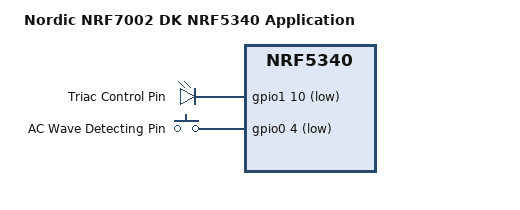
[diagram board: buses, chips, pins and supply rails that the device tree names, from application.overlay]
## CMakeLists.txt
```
#
# Copyright (c) 2021 Nordic Semiconductor ASA
#
# SPDX-License-Identifier: LicenseRef-Nordic-5-Clause
#

cmake_minimum_required(VERSION 3.20.0)

# Set Kconfig root files that will be processed as a first Kconfig for used child images.
set(mcuboot_KCONFIG_ROOT "\\\${ZEPHYR_CONNECTEDHOMEIP_MODULE_DIR}/config/nrfconnect/chip-module/Kconfig.mcuboot.root")
set(multiprotocol_rpmsg_KCONFIG_ROOT "\\\${ZEPHYR_CONNECTEDHOMEIP_MODULE_DIR}/config/nrfconnect/chip-module/Kconfig.multiprotocol_rpmsg.root")
set(hci_ipc_KCONFIG_ROOT "\\\${ZEPHYR_CONNECTEDHOMEIP_MODULE_DIR}/config/nrfconnect/chip-module/Kconfig.hci_ipc.root")

# For prj.conf the CONF_FILE is empty. In other case extract the exact file name from the path string.
if(CONF_FILE)
    get_filename_component(CONFIG_FILE_NAME ${CONF_FILE} NAME)
endif()

if(NOT "${CONFIG_FILE_NAME}" STREQUAL "prj_no_dfu.conf")
    set(PM_STATIC_YML_FILE ${CMAKE_CURRENT_SOURCE_DIR}/configuration/${BOARD}/pm_static_dfu.yml)
endif()

find_package(Zephyr HINTS $ENV{ZEPHYR_BASE})

project(matter-light-bulb)

# Enable GNU STD support and initialize the Matter Data Model.
include(${ZEPHYR_CONNECTEDHOMEIP_MODULE_DIR}/config/nrfconnect/app/enable-gnu-std.cmake)
include(${ZEPHYR_CONNECTEDHOMEIP_MODULE_DIR}/src/app/chip_data_model.cmake)

# NORDIC SDK APP START

# Include all source files that are located in the Matter common directory.
include(${ZEPHYR_NRF_MODULE_DIR}/samples/matter/common/cmake/source_common.cmake)

target_include_directories(app PRIVATE
    src
    src/bridged_device_types
    ${ZEPHYR_NRF_MODULE_DIR}/samples/matter/common/src/bridge/
    ${ZEPHYR_NRF_MODULE_DIR}/samples/matter/common/src/bridge/util
)

if(CONFIG_AWS_IOT_INTEGRATION)
    add_subdirectory(src/aws_iot_integration)
endif()

target_sources(app PRIVATE
    src/app_task.cpp
    src/main.cpp
    src/zcl_callbacks.cpp
    src/triac_controller.c
    src/ac_wave_detector.c
    src/bridge_shell.cpp
    ${ZEPHYR_NRF_MODULE_DIR}/samples/matter/common/src/bridge/bridge_manager.cpp
    ${ZEPHYR_NRF_MODULE_DIR}/samples/matter/common/src/bridge/matter_bridged_device.cpp
    ${ZEPHYR_NRF_MODULE_DIR}/samples/matter/common/src/bridge/bridge_storage_manager.cpp
    ${ZEPHYR_NRF_MODULE_DIR}/samples/matter/common/src/bridge/bridged_device_data_provider.cpp
    ${ZEPHYR_NRF_MODULE_DIR}/samples/matter/common/src/binding/binding_handler.cpp
    ${ZEPHYR_NRF_MODULE_DIR}/samples/matter/common/src/persistent_storage/persistent_storage_util.cpp
)

if(CONFIG_BRIDGED_DEVICE_BT)
    target_sources(app PRIVATE
         ${ZEPHYR_NRF_MODULE_DIR}/samples/matter/common/src/bridge/ble_connectivity_manager.cpp
        src/ble_providers/ble_bridged_device_factory.cpp
    )
    target_include_directories(app PRIVATE src/ble_providers)

if(CONFIG_BRIDGE_ONOFF_LIGHT_BRIDGED_DEVICE AND (CONFIG_BRIDGE_GENERIC_SWITCH_BRIDGED_DEVICE OR CONFIG_BRIDGE_ONOFF_LIGHT_SWITCH_BRIDGED_DEVICE))
    target_sources(app PRIVATE
        src/bridged_device_types/onoff_light.cpp
        src/ble_providers/ble_lbs_data_provider.cpp
    )

if(CONFIG_BRIDGE_GENERIC_SWITCH_BRIDGED_DEVICE)
    target_sources(app PRIVATE src/bridged_device_types/generic_switch.cpp)
endif()

if(CONFIG_BRIDGE_ONOFF_LIGHT_SWITCH_BRIDGED_DEVICE)
    target_sources(app PRIVATE
        src/bridged_device_types/onoff_light_switch.cpp
    )
endif()

endif() # CONFIG_BRIDGE_ONOFF_LIGHT_BRIDGED_DEVICE AND (CONFIG_BRIDGE_GENERIC_SWITCH_BRIDGED_DEVICE OR CONFIG_BRIDGE_ONOFF_LIGHT_SWITCH_BRIDGED_DEVICE)

if(CONFIG_BRIDGE_HUMIDITY_SENSOR_BRIDGED_DEVICE)
    target_sources(app PRIVATE
        src/bridged_device_types/humidity_sensor.cpp
    )
endif() # CONFIG_BRIDGE_HUMIDITY_SENSOR_BRIDGED_DEVICE

if(CONFIG_BRIDGE_TEMPERATURE_SENSOR_BRIDGED_DEVICE)
    target_sources(app PRIVATE
        src/bridged_device_types/temperature_sensor.cpp
    )
endif() # CONFIG_BRIDGE_TEMPERATURE_SENSOR_BRIDGED_DEVICE

# Assume it makes no sense to support BLE environmental sensor without all Matter counterparts
if(CONFIG_BRIDGE_TEMPERATURE_SENSOR_BRIDGED_DEVICE AND CONFIG_BRIDGE_HUMIDITY_SENSOR_BRIDGED_DEVICE)
    target_sources(app PRIVATE
        src/ble_providers/ble_environmental_data_provider.cpp
    )
endif() # CONFIG_BRIDGE_TEMPERATURE_SENSOR_BRIDGED_DEVICE AND CONFIG_BRIDGE_HUMIDITY_SENSOR_BRIDGED_DEVICE

else()
    target_sources(app PRIVATE
        src/simulated_providers/simulated_bridged_device_factory.cpp
    )
    target_include_directories(app PRIVATE src/simulated_providers)

if(CONFIG_BRIDGE_ONOFF_LIGHT_BRIDGED_DEVICE AND (CONFIG_BRIDGE_GENERIC_SWITCH_BRIDGED_DEVICE OR CONFIG_BRIDGE_ONOFF_LIGHT_SWITCH_BRIDGED_DEVICE))
    target_sources(app PRIVATE
        src/bridged_device_types/onoff_light.cpp
        src/simulated_providers/simulated_onoff_light_data_provider.cpp
    )

if(CONFIG_BRIDGE_GENERIC_SWITCH_BRIDGED_DEVICE)
    target_sources(app PRIVATE
        src/bridged_device_types/generic_switch.cpp
        src/simulated_providers/simulated_generic_switch_data_provider.cpp
    )
endif()

if(CONFIG_BRIDGE_ONOFF_LIGHT_SWITCH_BRIDGED_DEVICE)
    target_sources(app PRIVATE
        src/bridged_device_types/onoff_light_switch.cpp
        src/simulated_providers/simulated_onoff_light_switch_data_provider.cpp
    )
endif()

endif() # CONFIG_BRIDGE_ONOFF_LIGHT_BRIDGED_DEVICE AND (CONFIG_BRIDGE_GENERIC_SWITCH_BRIDGED_DEVICE OR CONFIG_BRIDGE_ONOFF_LIGHT_SWITCH_BRIDGED_DEVICE))

if(CONFIG_BRIDGE_TEMPERATURE_SENSOR_BRIDGED_DEVICE)
    target_sources(app PRIVATE
            src/bridged_device_types/temperature_sensor.cpp
            src/simulated_providers/simulated_temperature_sensor_data_provider.cpp
    )
endif() # CONFIG_BRIDGE_TEMPERATURE_SENSOR_BRIDGED_DEVICE

if(CONFIG_BRIDGE_HUMIDITY_SENSOR_BRIDGED_DEVICE)
    target_sources(app PRIVATE
        src/bridged_device_types/humidity_sensor.cpp
        src/simulated_providers/simulated_humidity_sensor_data_provider.cpp
    )
endif() # CONFIG_BRIDGE_HUMIDITY_SENSOR_BRIDGED_DEVICE

endif() # CONFIG_BRIDGED_DEVICE_BT

chip_configure_data_model(app
    INCLUDE_SERVER
    BYPASS_IDL
    GEN_DIR src/zap-generated
    ZAP_FILE ${CMAKE_CURRENT_SOURCE_DIR}/src/light_bulb.zap
)
# NORDIC SDK APP END
```

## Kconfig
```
#
# Copyright (c) 2022 Nordic Semiconductor
#
# SPDX-License-Identifier: LicenseRef-Nordic-5-Clause
#
mainmenu "Matter nRF Connect Light Bulb Example Application"

# Sample configuration used for Thread networking
if NET_L2_OPENTHREAD

choice OPENTHREAD_NORDIC_LIBRARY_CONFIGURATION
	default OPENTHREAD_NORDIC_LIBRARY_FTD
endchoice

choice OPENTHREAD_DEVICE_TYPE
	default OPENTHREAD_FTD
endchoice

endif # NET_L2_OPENTHREAD

config BRIDGE_ONOFF_LIGHT_BRIDGED_DEVICE
	bool "Support for OnOff Light bridged device"
	default y

config BRIDGE_TEMPERATURE_SENSOR_BRIDGED_DEVICE
	bool "Support for Temperature Sensor bridged device"
	default y

config BRIDGE_HUMIDITY_SENSOR_BRIDGED_DEVICE
	bool "Support for Humidity Sensor bridged device"
	default y

choice BRIDGE_SWITCH_BRIDGED_DEVICE
	prompt "Bridged device switch implementation"
	default BRIDGE_GENERIC_SWITCH_BRIDGED_DEVICE

config BRIDGE_GENERIC_SWITCH_BRIDGED_DEVICE
	bool "Support for Generic Switch bridged device"

config BRIDGE_ONOFF_LIGHT_SWITCH_BRIDGED_DEVICE
	bool "Support for OnOff Light Switch bridged device"

endchoice

choice BRIDGED_DEVICE_IMPLEMENTATION
	prompt "Bridged Device implementation"
	default BRIDGED_DEVICE_SIMULATED

	config BRIDGED_DEVICE_SIMULATED
		bool "Simulated Bridged Device"
		help
		  Enables using simulated bridged devices that do not perform
		  real operations, but emulate exemplary data to imitate the real
		  device behavior.

	config BRIDGED_DEVICE_BT
		bool "Bluetooth LE Bridged Device"
		help
		  Enables using real bridged devices that communicate with the Matter bridge device
		  over Bluetooth LE.

endchoice

if BRIDGED_DEVICE_SIMULATED

choice BRIDGED_DEVICE_SIMULATED_ONOFF_IMPLEMENTATION
	prompt "Simulated bridged onoff device implementation"
	default BRIDGED_DEVICE_SIMULATED_ONOFF_SHELL

	config BRIDGED_DEVICE_SIMULATED_ONOFF_AUTOMATIC
		bool "Automatically simulated bridged onoff device"
		help
		  Enables using simulated bridged onoff device that
		  automatically changes its state periodically.

	config BRIDGED_DEVICE_SIMULATED_ONOFF_SHELL
		bool "Shell controlled simulated bridged onoff device"
		help
		  Enables using simulated bridged onoff device that is
		  controlled by shell commands.

endchoice

endif

if BRIDGED_DEVICE_BT

config BT_CENTRAL
	default y

config BT_SCAN
	default y

# Configure how many Bluetooth LE devices the Matter bridge can support (the final number is given value - 1, as 1 connection is used for the Matter Bluetooth LE service).
config BT_MAX_CONN
	default 6

config BT_SCAN_FILTER_ENABLE
	default y

# Configure how many Bluetooth LE service UUIDs the Matter bridge can scan.
config BT_SCAN_UUID_CNT
	default 2

config BT_SCAN_ADDRESS_CNT
	default 1

config BT_GATT_CLIENT
	default y

config BT_GATT_DM
	default y

config BT_EXT_ADV
	default y

config BT_SMP
	default y

if BT_SMP

config BT_SETTINGS
	default y

# Configure how many Bluetooth LE devices will be paired with Matter bridge. Assuming it will be only bridged devices, it should be set to BT_MAX_CONN - 1.
config BT_MAX_PAIRED
	default 2

# Use two Bluetooth LE identities. The first one is used by the peripheral for Matter service advertising purposes, and the other is used by the Matter bridge central.
config BT_ID_MAX
	default 2

config BT_EXT_ADV_LEGACY_SUPPORT
	default y

endif

config BRIDGE_BLE_DEVICE_POLLING_INTERVAL
	int "BLE humidity measurement readout polling interval in ms"
	default 3000

endif

if BRIDGE_TEMPERATURE_SENSOR_BRIDGED_DEVICE

config BRIDGE_TEMPERATURE_SENSOR_MIN_MEASURED_VALUE
	int "Default minimum measured value allowed by the bridged temperature sensor device"
	default -20

config BRIDGE_TEMPERATURE_SENSOR_MAX_MEASURED_VALUE
	int "Default maximum measured value allowed by the bridged temperature sensor device"
	default 60

endif

if BRIDGE_HUMIDITY_SENSOR_BRIDGED_DEVICE

config BRIDGE_HUMIDITY_SENSOR_MIN_MEASURED_VALUE
	int "Default minimum measured value allowed by the bridged humidity sensor device"
	default 0

config BRIDGE_HUMIDITY_SENSOR_MAX_MEASURED_VALUE
	int "Default maximum measured value allowed by the bridged humidity sensor device"
	default 100

endif

# Enable Read Client functionality for all build configurations.
config CHIP_ENABLE_READ_CLIENT
	default y

source "${ZEPHYR_CONNECTEDHOMEIP_MODULE_DIR}/config/nrfconnect/chip-module/Kconfig.features"
source "${ZEPHYR_CONNECTEDHOMEIP_MODULE_DIR}/config/nrfconnect/chip-module/Kconfig.defaults"
source "${ZEPHYR_NRF_MODULE_DIR}/samples/matter/common/src/bridge/Kconfig"
source "${ZEPHYR_NRF_MODULE_DIR}/samples/matter/common/src/Kconfig"
source "Kconfig.zephyr"
rsource "src/aws_iot_integration/Kconfig"
```

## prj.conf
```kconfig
#
# Copyright (c) 2022 Nordic Semiconductor ASA
#
# SPDX-License-Identifier: LicenseRef-Nordic-5-Clause
#
CONFIG_LOG=y

# Enable CHIP
CONFIG_CHIP=y
CONFIG_CHIP_PROJECT_CONFIG="src/chip_project_config.h"
# 32773 == 0x8005 (example lighting-app)
CONFIG_CHIP_DEVICE_PRODUCT_ID=32773
CONFIG_STD_CPP17=y

# Enable CHIP pairing automatically on application start.
CONFIG_CHIP_ENABLE_PAIRING_AUTOSTART=y

# Add support for LEDs and buttons on Nordic development kits
CONFIG_DK_LIBRARY=n
CONFIG_PWM=y

# Bluetooth Low Energy configuration
CONFIG_BT_DEVICE_NAME="MatterLight"

# Other settings
CONFIG_THREAD_NAME=y
CONFIG_MPU_STACK_GUARD=y
CONFIG_RESET_ON_FATAL_ERROR=n
CONFIG_CHIP_LIB_SHELL=y

# Reduce application size
CONFIG_USE_SEGGER_RTT=n

# Enable Factory Data feature
CONFIG_CHIP_FACTORY_DATA=y
CONFIG_CHIP_FACTORY_DATA_BUILD=y

CONFIG_MCUBOOT_IMGTOOL_SIGN_VERSION="2.6.0+0"

CONFIG_ASSERT_NO_FILE_INFO=y
CONFIG_CHIP_NFC_COMMISSIONING=n
CONFIG_BRIDGED_DEVICE_BT=y
```

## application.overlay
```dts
/ {
  model = "Nordic NRF7002 DK NRF5340 Application";
  compatible = "nordic,nrf7002-dk-nrf5340-cpuapp";

  leds {
    compatible = "gpio-leds";
    led0: led_0 {
      gpios = <&gpio1 10 GPIO_ACTIVE_LOW>;
      label = "Triac Control Pin";
    };
  };

  buttons {
    compatible = "gpio-keys";
    button0: button_0 {
      gpios = <&gpio0 4 (GPIO_ACTIVE_LOW)>;
      label = "AC Wave Detecting Pin";
    };
  };
};
```

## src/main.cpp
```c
/*
 * Copyright (c) 2021 Nordic Semiconductor ASA
 *
 * SPDX-License-Identifier: LicenseRef-Nordic-5-Clause
 */

extern "C" {
	#include "ac_wave_detector.h"
	#include "triac_controller.h"
}

#include "app_task.h"

#include <zephyr/logging/log.h>

LOG_MODULE_REGISTER(app, CONFIG_CHIP_APP_LOG_LEVEL);

void new_ac_wave_detected(void)
{
	start_triac_on_timer();
}

int main()
{
	int err_c;
	err_c = init_ac_wave_detector(new_ac_wave_detected);
	if(err_c)
	{
		printk("Failed to init ac wave detector\n");
		return err_c;
	}

	err_c = init_triac_controller();
	if(err_c)
	{
		printk("Failed to init triac controller\n");
		return err_c;
	}

	enable_ac_wave_detector();

	change_triac_enabled_state(true);
	change_triac_brightness_level(10);

 	k_msleep(1000);

	CHIP_ERROR err = AppTask::Instance().StartApp();

	LOG_ERR("Exited with code %" CHIP_ERROR_FORMAT, err.Format());
	return err == CHIP_NO_ERROR ? EXIT_SUCCESS : EXIT_FAILURE;
}
```

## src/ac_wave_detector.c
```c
/******************************************************************************************
 *
 * @file        ac_wave_detector.h
 *
 * @brief       Detects new AC wave signal
 *
 * @details     Calls the callback provided when a new AC wave is detected
 *
 * @author(s)   Joe Rippee
 *
 * @created     2/09/2024   (MM/DD/YYYY)
 * 
 * @copyright       © 2024 SWYM, LLC. All Rights Reserved
 *
 *****************************************************************************************/

#include <zephyr/drivers/gpio.h>
#include <zephyr/kernel.h>
#include <zephyr/sys/printk.h>

#include "ac_wave_detector.h"

#define AC_WAVE_STACK_SIZE  1024
#define AC_WAVE_THD_PRIO    10

/*
 * Get button configuration from the devicetree sw0 alias. This is mandatory.
 */
#define SW0_NODE        DT_ALIAS(sw0)
#if !DT_NODE_HAS_STATUS(SW0_NODE, okay)
#error "Unsupported board: sw0 devicetree alias is not defined"
#endif

K_THREAD_STACK_DEFINE(ac_wave_stack, AC_WAVE_STACK_SIZE);
struct k_work_q ac_wave_q;

static struct k_work ac_wave_handler;

static const struct gpio_dt_spec ac_wave_detector_gpio = GPIO_DT_SPEC_GET_OR(SW0_NODE, gpios,
                                                              {0});
static struct gpio_callback ac_wave_cb_data;

void (*main_ac_wave_detected_callback)(void) = NULL;

/*
  Parameter: k_work pointer
  Returns: N/A

  gets called by a work queue if new AC wave is detected
  simply alerts the main program that a new AC wave was detected
*/
void ac_wave_work_handler(struct k_work *work) {
  if(NULL != main_ac_wave_detected_callback) {
    main_ac_wave_detected_callback();
  }
}

/*
  Parameter: 
    which button port was pressed/depressed
    a struct holding gpio callback info
    which button pin was pressed/depressed
  Returns: N/A

  Triggers on button rising and falling edge
  The onboard press detect chip seems to handle de-bounce quite well

  If button is pressed, start a timer
  If button is de-pressed, end timer
*/
void ac_wave_detected(const struct device *dev, struct gpio_callback *cb,
                    uint32_t pins)
{
  int val = gpio_pin_get_dt(&ac_wave_detector_gpio);
  if (val >= 0) {
    int k_work_status = k_work_submit_to_queue(&ac_wave_q, &ac_wave_handler);
    if(0 > k_work_status) {
      printk("[ac_wave_detector]: Could not submit ac wave detection to queue due to %i!\n", k_work_status);
    }
  }
}

/*
  Parameter: N/A
  Returns: status variable for capacative button enable GPIO initialization

  this GPIO must be high for button detection to work due to the PCB layout
  returns 0 if initialization was successful
*/
/*
  Parameter: N/A
  Returns: status variable for capacative button GPIO initialization

  enables the capacative button on the wristband
  provides callback for when button is pressed/depressed
  returns 0 if initialization was successful
*/
int initialize_ac_detect_gpio(void)
{
  int err = 0;

  if (!gpio_is_ready_dt(&ac_wave_detector_gpio)) {
    printk("Error: ac_wave_detector_gpio device %s is not ready\n",
           ac_wave_detector_gpio.port->name);
    err += -ENODEV;
  }
  
  err += gpio_pin_configure_dt(&ac_wave_detector_gpio, GPIO_INPUT);
  if (err != 0) {
    printk("Error %d: failed to configure %s pin %d\n",
           err, ac_wave_detector_gpio.port->name, ac_wave_detector_gpio.pin);
  }
  
  err += gpio_pin_interrupt_configure_dt(&ac_wave_detector_gpio,
                                      GPIO_INT_EDGE_FALLING);
  if (err != 0) {
    printk("Error %d: failed to configure interrupt on %s pin %d\n",
        err, ac_wave_detector_gpio.port->name, ac_wave_detector_gpio.pin);
  }
  
  gpio_init_callback(&ac_wave_cb_data, ac_wave_detected, BIT(ac_wave_detector_gpio.pin));

  return err;
}

/*
  Parameter: void function pointer for when new AC wave is detected
  Returns: status variable for ac wave detection initialization. 0 = success

  Initializes the ac wave detector with edge detect interrupts (rising edge only)
  Provided callback is stored in a unique private function pointer
*/
int init_ac_wave_detector(void (*ac_wave_detected_callback)(void))
{
  int err = 0;

  main_ac_wave_detected_callback = ac_wave_detected_callback;
  err += initialize_ac_detect_gpio();

  if(0 == err) {
    k_work_init(&ac_wave_handler, ac_wave_work_handler);

    k_work_queue_start(
      &ac_wave_q,
      ac_wave_stack,
      K_THREAD_STACK_SIZEOF(ac_wave_stack),
      AC_WAVE_THD_PRIO,
      NULL
    );
  }

  return err;
}

void enable_ac_wave_detector(void)
{
  gpio_add_callback(ac_wave_detector_gpio.port, &ac_wave_cb_data);
}
```

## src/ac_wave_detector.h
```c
/******************************************************************************************
 *
 * @file        ac_wave_detector.h
 *
 * @brief       Detects new AC wave signal
 *
 * @details     Calls the callback provided when a new AC wave is detected
 *
 * @author(s)   Joe Rippee
 *
 * @created     2/09/2024   (MM/DD/YYYY)
 * 
 * @copyright       © 2024 SWYM, LLC. All Rights Reserved
 *
 *****************************************************************************************/

#ifndef AC_WAVE_DETECTOR_H__
#define AC_WAVE_DETECTOR_H__

/*
  Parameter: void function pointer for when new AC wave is detected
  Returns: status variable for ac wave detection initialization. 0 = success

  Initializes the ac wave detector with edge detect interrupts (rising edge only)
  Provided callback is stored in a unique private function pointer
*/
int init_ac_wave_detector(void (*ac_wave_detected_callback)(void));

void enable_ac_wave_detector(void);

#endif
```

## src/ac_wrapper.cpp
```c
#include "ac_wrapper.h"

AcWrapper* AcWrapper::instance = nullptr;

AcWrapper::AcWrapper() {
    instance = this;
}

AcWrapper::~AcWrapper() {
    instance = nullptr;
}

int AcWrapper::init(std::function<void()> callback) {
    this->acWaveDetectedCallback = callback;
    return init_ac_wave_detector(cStyleCallback);
}

void AcWrapper::enable() {
    enable_ac_wave_detector();
}

void AcWrapper::cStyleCallback() {
    if (instance != nullptr && instance->acWaveDetectedCallback) {
        instance->acWaveDetectedCallback();
    }
}
```

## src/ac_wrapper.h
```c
#ifndef AC_WRAPPER_H
#define AC_WRAPPER_H

#include <functional>

extern "C" {
    #include "ac_wave_detector.h"
}

class AcWrapper {
public:
    AcWrapper();
    ~AcWrapper();

    int init(std::function<void()> acWaveDetectedCallback);
    void enable();

private:
    static void cStyleCallback();

    std::function<void()> acWaveDetectedCallback;
    static AcWrapper* instance;
};

#endif // AC_WRAPPER_H
```

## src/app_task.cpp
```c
/*
 * Copyright (c) 2021 Nordic Semiconductor ASA
 *
 * SPDX-License-Identifier: LicenseRef-Nordic-5-Clause
 */

#include "app_task.h"

#ifdef CONFIG_BRIDGED_DEVICE_BT
#include "ble_bridged_device_factory.h"
#else
#include "simulated_bridged_device_factory.h"
#endif /* CONFIG_BRIDGED_DEVICE_BT */

#ifdef CONFIG_AWS_IOT_INTEGRATION
#include "aws_iot_integration.h"
#endif

#include "app/matter_init.h"
#include "app/task_executor.h"
#include "board/board.h"
#include "bridge/bridge_manager.h"
#include "bridge/bridge_storage_manager.h"
#include "pwm/pwm_device.h"

#ifdef CONFIG_BRIDGED_DEVICE_BT
#include "bridge/ble_connectivity_manager.h"
#endif

#ifdef CONFIG_CHIP_OTA_REQUESTOR
#include "dfu/ota/ota_util.h"
#endif

#include <app-common/zap-generated/ids/Attributes.h>
#include <app-common/zap-generated/ids/Clusters.h>
#include <app/server/OnboardingCodesUtil.h>

#include <app-common/zap-generated/attributes/Accessors.h>
#include <app/DeferredAttributePersistenceProvider.h>
#include <app/clusters/identify-server/identify-server.h>
#include <app/server/OnboardingCodesUtil.h>
#include <app/server/Server.h>

#ifdef CONFIG_BRIDGED_DEVICE_BT
#include <bluetooth/services/lbs.h>
#endif /* CONFIG_BRIDGED_DEVICE_BT */
#include <zephyr/logging/log.h>

LOG_MODULE_DECLARE(app, CONFIG_CHIP_APP_LOG_LEVEL);

using namespace ::chip;
using namespace ::chip::app;
using namespace ::chip::DeviceLayer;

namespace
{
#ifdef CONFIG_BRIDGED_DEVICE_BT
static bt_uuid *sUuidLbs = BT_UUID_LBS;
static bt_uuid *sUuidEs = BT_UUID_ESS;
static bt_uuid *sUuidServices[] = { sUuidLbs, sUuidEs };
static constexpr uint8_t kUuidServicesNumber = ARRAY_SIZE(sUuidServices);
/**
 * @brief Blink rates for indication the BLE Connectivity Manager state.
 *
 */
constexpr static uint32_t kPairingBlinkRate{ 100 };
constexpr static uint32_t kScanningBlinkRate_ms{ 300 };
constexpr static uint32_t kLostBlinkRate_ms{ 1000 };

void BLEStateChangeCallback(Nrf::BLEConnectivityManager::State state)
{
	switch (state) {
	case Nrf::BLEConnectivityManager::State::Connected:
		Nrf::PostTask([] { Nrf::GetBoard().GetLED(Nrf::DeviceLeds::LED2).Set(true); });
		break;
	case Nrf::BLEConnectivityManager::State::Scanning:
		Nrf::PostTask([] {
			Nrf::GetBoard()
				.GetLED(Nrf::DeviceLeds::LED2)
				.Blink(kScanningBlinkRate_ms, kScanningBlinkRate_ms);
		});
		break;
	case Nrf::BLEConnectivityManager::State::LostDevice:
		Nrf::PostTask([] {
			Nrf::GetBoard().GetLED(Nrf::DeviceLeds::LED2).Blink(kLostBlinkRate_ms, kLostBlinkRate_ms);
		});
		break;
	case Nrf::BLEConnectivityManager::State::Pairing:
		Nrf::PostTask([] {
			Nrf::GetBoard().GetLED(Nrf::DeviceLeds::LED2).Blink(kPairingBlinkRate, kPairingBlinkRate);
		});
		break;
	default:
		Nrf::PostTask([] { Nrf::GetBoard().GetLED(Nrf::DeviceLeds::LED2).Set(false); });
	}
}

#endif /* CONFIG_BRIDGED_DEVICE_BT */

constexpr EndpointId kLightEndpointId = 1;
constexpr uint8_t kDefaultMinLevel = 0;
constexpr uint8_t kDefaultMaxLevel = 254;
constexpr uint16_t kTriggerEffectTimeout = 5000;
constexpr uint16_t kTriggerEffectFinishTimeout = 1000;

k_timer sTriggerEffectTimer;

Identify sIdentify = { kLightEndpointId, AppTask::IdentifyStartHandler, AppTask::IdentifyStopHandler,
		       Clusters::Identify::IdentifyTypeEnum::kVisibleIndicator, AppTask::TriggerIdentifyEffectHandler };

bool sIsTriggerEffectActive = false;

const struct pwm_dt_spec sLightPwmDevice = PWM_DT_SPEC_GET(DT_ALIAS(pwm_led1));

// Define a custom attribute persister which makes actual write of the CurrentLevel attribute value
// to the non-volatile storage only when it has remained constant for 5 seconds. This is to reduce
// the flash wearout when the attribute changes frequently as a result of MoveToLevel command.
// DeferredAttribute object describes a deferred attribute, but also holds a buffer with a value to
// be written, so it must live so long as the DeferredAttributePersistenceProvider object.
DeferredAttribute gCurrentLevelPersister(ConcreteAttributePath(kLightEndpointId, Clusters::LevelControl::Id,
							       Clusters::LevelControl::Attributes::CurrentLevel::Id));
DeferredAttributePersistenceProvider gDeferredAttributePersister(Server::GetInstance().GetDefaultAttributePersister(),
								 Span<DeferredAttribute>(&gCurrentLevelPersister, 1),
								 System::Clock::Milliseconds32(5000));

#define APPLICATION_BUTTON_MASK DK_BTN2_MSK
} /* namespace */

void AppTask::IdentifyStartHandler(Identify *)
{
	Nrf::PostTask(
		[] { Nrf::GetBoard().GetLED(Nrf::DeviceLeds::LED2).Blink(Nrf::LedConsts::kIdentifyBlinkRate_ms); });
}

void AppTask::IdentifyStopHandler(Identify *)
{
	Nrf::PostTask([] {
		Nrf::GetBoard().GetLED(Nrf::DeviceLeds::LED2).Set(false);
		Instance().mPWMDevice.ApplyLevel();
	});
}

void AppTask::TriggerEffectTimerTimeoutCallback(k_timer *timer)
{
	LOG_INF("Identify effect completed");

	sIsTriggerEffectActive = false;

	Nrf::GetBoard().GetLED(Nrf::DeviceLeds::LED2).Set(false);
	Instance().mPWMDevice.ApplyLevel();
}

void AppTask::TriggerIdentifyEffectHandler(Identify *identify)
{
	switch (identify->mCurrentEffectIdentifier) {
	/* Just handle all effects in the same way. */
	case Clusters::Identify::EffectIdentifierEnum::kBlink:
	case Clusters::Identify::EffectIdentifierEnum::kBreathe:
	case Clusters::Identify::EffectIdentifierEnum::kOkay:
	case Clusters::Identify::EffectIdentifierEnum::kChannelChange:
		LOG_INF("Identify effect identifier changed to %d",
			static_cast<uint8_t>(identify->mCurrentEffectIdentifier));

		sIsTriggerEffectActive = false;

		k_timer_stop(&sTriggerEffectTimer);
		k_timer_start(&sTriggerEffectTimer, K_MSEC(kTriggerEffectTimeout), K_NO_WAIT);

		Instance().mPWMDevice.SuppressOutput();
		Nrf::GetBoard().GetLED(Nrf::DeviceLeds::LED2).Blink(Nrf::LedConsts::kIdentifyBlinkRate_ms);

		break;
	case Clusters::Identify::EffectIdentifierEnum::kFinishEffect:
		LOG_INF("Identify effect finish triggered");
		k_timer_stop(&sTriggerEffectTimer);
		k_timer_start(&sTriggerEffectTimer, K_MSEC(kTriggerEffectFinishTimeout), K_NO_WAIT);
		break;
	case Clusters::Identify::EffectIdentifierEnum::kStopEffect:
		if (sIsTriggerEffectActive) {
			sIsTriggerEffectActive = false;

			k_timer_stop(&sTriggerEffectTimer);

			Nrf::GetBoard().GetLED(Nrf::DeviceLeds::LED2).Set(false);
			Instance().mPWMDevice.ApplyLevel();
		}
		break;
	default:
		LOG_ERR("Received invalid effect identifier.");
		break;
	}
}

void AppTask::LightingActionEventHandler(const LightingEvent &event)
{
	Nrf::PWMDevice::Action_t action = Nrf::PWMDevice::INVALID_ACTION;
	int32_t actor = 0;
	if (event.Actor == LightingActor::Remote) {
		action = static_cast<Nrf::PWMDevice::Action_t>(event.Action);
		actor = static_cast<int32_t>(event.Actor);
	} else if (event.Actor == LightingActor::Button) {
		action = Instance().mPWMDevice.IsTurnedOn() ? Nrf::PWMDevice::OFF_ACTION : Nrf::PWMDevice::ON_ACTION;
		actor = static_cast<int32_t>(event.Actor);
	}

	if (action == Nrf::PWMDevice::INVALID_ACTION || !Instance().mPWMDevice.InitiateAction(action, actor, NULL)) {
		LOG_INF("An action could not be initiated.");
	}
}

void AppTask::ButtonEventHandler(Nrf::ButtonState state, Nrf::ButtonMask hasChanged)
{
	if ((APPLICATION_BUTTON_MASK & hasChanged) & state) {
		Nrf::PostTask([] {
			LightingEvent event;
			event.Actor = LightingActor::Button;
			LightingActionEventHandler(event);
		});
	}
}

#ifdef CONFIG_AWS_IOT_INTEGRATION
bool AppTask::AWSIntegrationCallback(struct aws_iot_integration_cb_data *data)
{
	LOG_INF("Attribute change requested from AWS IoT: %d", data->value);

	EmberAfStatus status;

	VerifyOrDie(data->error == 0);

	if (data->attribute_id == ATTRIBUTE_ID_ONOFF) {
		/* write the new on/off value */
		status = Clusters::OnOff::Attributes::OnOff::Set(kLightEndpointId, data->value);
		if (status != EMBER_ZCL_STATUS_SUCCESS) {
			LOG_ERR("Updating on/off cluster failed: %x", status);
			return false;
		}
	} else if (data->attribute_id == ATTRIBUTE_ID_LEVEL_CONTROL) {
		/* write the current level */
		status = Clusters::LevelControl::Attributes::CurrentLevel::Set(kLightEndpointId, data->value);

		if (status != EMBER_ZCL_STATUS_SUCCESS) {
			LOG_ERR("Updating level cluster failed: %x", status);
			return false;
		}
	}

	return true;
}
#endif /* CONFIG_AWS_IOT_INTEGRATION */

void AppTask::ActionInitiated(Nrf::PWMDevice::Action_t action, int32_t actor)
{
	if (action == Nrf::PWMDevice::ON_ACTION) {
		LOG_INF("Turn On Action has been initiated");
	} else if (action == Nrf::PWMDevice::OFF_ACTION) {
		LOG_INF("Turn Off Action has been initiated");
	} else if (action == Nrf::PWMDevice::LEVEL_ACTION) {
		LOG_INF("Level Action has been initiated");
	}
}

void AppTask::ActionCompleted(Nrf::PWMDevice::Action_t action, int32_t actor)
{
	if (action == Nrf::PWMDevice::ON_ACTION) {
		LOG_INF("Turn On Action has been completed");
	} else if (action == Nrf::PWMDevice::OFF_ACTION) {
		LOG_INF("Turn Off Action has been completed");
	} else if (action == Nrf::PWMDevice::LEVEL_ACTION) {
		LOG_INF("Level Action has been completed");
	}

	if (actor == static_cast<int32_t>(LightingActor::Button)) {
		Instance().UpdateClusterState();
	}
}

void AppTask::UpdateClusterState()
{
	SystemLayer().ScheduleLambda([this] {
		/* write the new on/off value */
		EmberAfStatus status =
			Clusters::OnOff::Attributes::OnOff::Set(kLightEndpointId, mPWMDevice.IsTurnedOn());

		if (status != EMBER_ZCL_STATUS_SUCCESS) {
			LOG_ERR("Updating on/off cluster failed: %x", status);
		}

		/* write the current level */
		status = Clusters::LevelControl::Attributes::CurrentLevel::Set(kLightEndpointId, mPWMDevice.GetLevel());

		if (status != EMBER_ZCL_STATUS_SUCCESS) {
			LOG_ERR("Updating level cluster failed: %x", status);
		}
	});
}

CHIP_ERROR AppTask::RestoreBridgedDevices()
{
	uint8_t count;
	uint8_t indexes[Nrf::BridgeManager::kMaxBridgedDevices] = { 0 };
	size_t indexesCount = 0;

	if (!Nrf::BridgeStorageManager::Instance().LoadBridgedDevicesCount(count)) {
		LOG_INF("No bridged devices to load from the storage.");
		return CHIP_NO_ERROR;
	}

	if (!Nrf::BridgeStorageManager::Instance().LoadBridgedDevicesIndexes(
		    indexes, Nrf::BridgeManager::kMaxBridgedDevices, indexesCount)) {
		return CHIP_NO_ERROR;
	}

	/* Load all devices based on the read count number. */
	for (size_t i = 0; i < indexesCount; i++) {
		uint16_t endpointId;
		char label[Nrf::MatterBridgedDevice::kNodeLabelSize] = { 0 };
		size_t labelSize;
		uint16_t deviceType;

		if (!Nrf::BridgeStorageManager::Instance().LoadBridgedDeviceEndpointId(endpointId, indexes[i])) {
			return CHIP_ERROR_NOT_FOUND;
		}

		/* Ignore an error, as node label is optional, so it may not be found. */
		Nrf::BridgeStorageManager::Instance().LoadBridgedDeviceNodeLabel(label, sizeof(label), labelSize,
										 indexes[i]);

		if (!Nrf::BridgeStorageManager::Instance().LoadBridgedDeviceType(deviceType, indexes[i])) {
			return CHIP_ERROR_NOT_FOUND;
		}

		LOG_INF("Loaded bridged device on endpoint id %d from the storage", endpointId);

#ifdef CONFIG_BRIDGED_DEVICE_BT
		bt_addr_le_t addr;

		if (!Nrf::BridgeStorageManager::Instance().LoadBtAddress(addr, indexes[i])) {
			return CHIP_ERROR_NOT_FOUND;
		}

		BleBridgedDeviceFactory::CreateDevice(deviceType, addr, label, indexes[i], endpointId);
#else
		SimulatedBridgedDeviceFactory::CreateDevice(deviceType, label, chip::Optional<uint8_t>(indexes[i]),
							    chip::Optional<uint16_t>(endpointId));
#endif
	}
	return CHIP_NO_ERROR;
}

CHIP_ERROR AppTask::Init()
{
	/* Initialize Matter stack */
	ReturnErrorOnFailure(Nrf::Matter::PrepareServer(Nrf::Matter::InitData{ .mPostServerInitClbk = [] {
#ifdef CONFIG_BRIDGED_DEVICE_BT
		Nrf::BLEConnectivityManager::Instance().RegisterStateCallback(BLEStateChangeCallback);
		/* Initialize BLE Connectivity Manager before the Bridge Manager, as it must be ready to recover
		 * devices loaded from persistent storage during the bridge init. */
		CHIP_ERROR bleInitError =
			Nrf::BLEConnectivityManager::Instance().Init(sUuidServices, kUuidServicesNumber);
		if (bleInitError != CHIP_NO_ERROR) {
			LOG_ERR("BLEConnectivityManager initialization failed");
			return bleInitError;
		}
#endif

		/* Initialize bridge manager */
		CHIP_ERROR bridgeMgrInitError = Nrf::BridgeManager::Instance().Init(RestoreBridgedDevices);
		if (bridgeMgrInitError != CHIP_NO_ERROR) {
			LOG_ERR("BridgeManager initialization failed");
			return bridgeMgrInitError;
		}
		return CHIP_NO_ERROR;
	} }));

	if (!Nrf::GetBoard().Init(ButtonEventHandler)) {
		LOG_ERR("User interface initialization failed.");
		return CHIP_ERROR_INCORRECT_STATE;
	}

	/* Register Matter event handler that controls the connectivity status LED based on the captured Matter network
	 * state. */
	ReturnErrorOnFailure(Nrf::Matter::RegisterEventHandler(Nrf::Board::DefaultMatterEventHandler, 0));

	int ret{};
#ifdef CONFIG_AWS_IOT_INTEGRATION
	ret = aws_iot_integration_register_callback(AWSIntegrationCallback);
	if (ret) {
		LOG_ERR("aws_iot_integration_register_callback() failed");
		return chip::System::MapErrorZephyr(ret);
	}
#endif

	/* Initialize trigger effect timer */
	k_timer_init(&sTriggerEffectTimer, &AppTask::TriggerEffectTimerTimeoutCallback, nullptr);

	/* Initialize lighting device (PWM) */
	uint8_t minLightLevel = kDefaultMinLevel;
	Clusters::LevelControl::Attributes::MinLevel::Get(kLightEndpointId, &minLightLevel);

	uint8_t maxLightLevel = kDefaultMaxLevel;
	Clusters::LevelControl::Attributes::MaxLevel::Get(kLightEndpointId, &maxLightLevel);

	ret = mPWMDevice.Init(&sLightPwmDevice, minLightLevel, maxLightLevel, maxLightLevel);
	if (ret != 0) {
		return chip::System::MapErrorZephyr(ret);
	}
	mPWMDevice.SetCallbacks(ActionInitiated, ActionCompleted);

	return Nrf::Matter::StartServer();
}

CHIP_ERROR AppTask::StartApp()
{
	ReturnErrorOnFailure(Init());

	while (true) {
		Nrf::DispatchNextTask();
	}

	return CHIP_NO_ERROR;
}
```

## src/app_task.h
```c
/*
 * Copyright (c) 2021 Nordic Semiconductor ASA
 *
 * SPDX-License-Identifier: LicenseRef-Nordic-5-Clause
 */

#pragma once

#include "board/board.h"
#include "pwm/pwm_device.h"

#include <platform/CHIPDeviceLayer.h>

struct k_timer;
struct Identify;

enum class LightingActor : uint8_t { Remote, Button };

struct LightingEvent {
	uint8_t Action;
	LightingActor Actor;
};

class AppTask {
public:
	static AppTask &Instance()
	{
		static AppTask sAppTask;
		return sAppTask;
	};

	CHIP_ERROR StartApp();

	void UpdateClusterState();
	Nrf::PWMDevice &GetPWMDevice() { return mPWMDevice; }

	static void IdentifyStartHandler(Identify *);
	static void IdentifyStopHandler(Identify *);
	static void TriggerIdentifyEffectHandler(Identify *);
	static void TriggerEffectTimerTimeoutCallback(k_timer *timer);

private:
	CHIP_ERROR Init();

	static CHIP_ERROR RestoreBridgedDevices();

	static void LightingActionEventHandler(const LightingEvent &event);
	static void ButtonEventHandler(Nrf::ButtonState state, Nrf::ButtonMask hasChanged);

	static void ActionInitiated(Nrf::PWMDevice::Action_t action, int32_t actor);
	static void ActionCompleted(Nrf::PWMDevice::Action_t action, int32_t actor);

#ifdef CONFIG_AWS_IOT_INTEGRATION
	static bool AWSIntegrationCallback(struct aws_iot_integration_cb_data *data);
#endif

	Nrf::PWMDevice mPWMDevice;
};
```

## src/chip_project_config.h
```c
/*
 * Copyright (c) 2021 Nordic Semiconductor ASA
 *
 * SPDX-License-Identifier: LicenseRef-Nordic-5-Clause
 */

/**
 *    @file
 *          Example project configuration file for CHIP.
 *
 *          This is a place to put application or project-specific overrides
 *          to the default configuration values for general CHIP features.
 *
 */

#pragma once

#define CHIP_CONFIG_LOG_MODULE_Zcl_PROGRESS 0
#define CHIP_CONFIG_LOG_MODULE_InteractionModel_PROGRESS 0
#define CHIP_CONFIG_LOG_MODULE_InteractionModel_DETAIL 0
#define CHIP_CONFIG_LOG_MODULE_DataManagement_PROGRESS 0
#define CHIP_CONFIG_LOG_MODULE_FabricProvisioning_PROGRESS 0
#define CHIP_CONFIG_LOG_MODULE_SecureChannel_PROGRESS 0
#define CHIP_CONFIG_LOG_MODULE_AppServer_PROGRESS 0

#define CHIP_DEVICE_CONFIG_DYNAMIC_ENDPOINT_COUNT CONFIG_BRIDGE_MAX_DYNAMIC_ENDPOINTS_NUMBER
```

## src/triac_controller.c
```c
/******************************************************************************************
 *
 * @file        triac_controller.c
 *
 * @brief       Controls Triac On/Off states
 *
 * @details     Accepts inputs for if Triac is enabled/disabled, and for how long
 *
 * @author(s)   Joe Rippee
 *
 * @created     2/12/2024   (MM/DD/YYYY)
 * 
 * @copyright       © 2024 SWYM, LLC. All Rights Reserved
 *
 *****************************************************************************************/

#include <zephyr/drivers/gpio.h>
#include <zephyr/kernel.h>
#include <zephyr/sys/printk.h>

#include "triac_controller.h"

/*
 * The led0 devicetree alias is optional. If present, we'll use it
 * to turn on the LED whenever the button is pressed.
 */
struct gpio_dt_spec triac = GPIO_DT_SPEC_GET_OR(DT_ALIAS(led0), gpios, {0});

//4.2
const uint8_t LOWEST_BRIGHTNESS_LEVEL = 1;
const uint8_t HIGHEST_BRIGHTNESS_LEVEL = 10;

const uint32_t FREQUENCY_OF_AC_SIGNAL = 120;
const uint32_t NUMBER_OF_BRIGHTNESS_DIVISIONS = 10; 
const uint32_t NUMBER_OF_MS_IN_A_SEC = 1000;
const uint32_t NUMBER_OF_US_IN_A_MSEC = 1000;
const double DUTY_CYCLE = 1.0;
//We are working off Sine wave, and need to sync off zero
const double msec_offset_needed = 6.22135; 
uint32_t number_of_ticks_to_delay = 0;
uint32_t number_of_ticks_per_brightness_division = 0;
uint32_t triac_brightness_level = 10; //1 is the lowest, 10 is the highest
//Default to triac disabled for safety reasons
bool triac_enabled = false;

const int TRIAC_ON_STATE  = 1;
const int TRIAC_OFF_STATE = 0;

struct k_sem triac_enabled_sem;
struct k_sem brightness_level_sem;

void timer_expired_handler(struct k_timer *timer);
void delay_timer_expired_handler(struct k_timer *timer);

K_TIMER_DEFINE(brightness_timer, timer_expired_handler, NULL);
K_TIMER_DEFINE(delay_timer, delay_timer_expired_handler, NULL);


void timer_expired_handler(struct k_timer *timer)
{
  gpio_pin_set_dt(&triac, TRIAC_OFF_STATE);
}

void delay_timer_expired_handler(struct k_timer *timer)
{
  k_timer_start(
    &brightness_timer, 
    K_CYC(
      number_of_ticks_per_brightness_division*triac_brightness_level
    ), 
    K_NO_WAIT
  );  
  gpio_pin_set_dt(&triac, TRIAC_ON_STATE);
}

void start_triac_on_timer(void)
{
  if(true == triac_enabled) {
    k_timer_start(&delay_timer, K_CYC(number_of_ticks_to_delay), K_NO_WAIT);
  }
}

void calculate_time_frame(void)
{
  double ms_per_brightness_division = NUMBER_OF_MS_IN_A_SEC * 1.0;
  ms_per_brightness_division /= (
    FREQUENCY_OF_AC_SIGNAL * NUMBER_OF_BRIGHTNESS_DIVISIONS
  );
  uint32_t number_of_ticks_per_sec = sys_clock_hw_cycles_per_sec();
  printk("Number of hw cycles per second = %i\n", number_of_ticks_per_sec);
  double number_of_ticks_per_msec = 1.0 * number_of_ticks_per_sec;
  number_of_ticks_per_msec /= NUMBER_OF_MS_IN_A_SEC;
  number_of_ticks_to_delay = (uint32_t)(
    number_of_ticks_per_msec * msec_offset_needed
  );
  number_of_ticks_per_brightness_division = (uint32_t)(
    number_of_ticks_per_msec * ms_per_brightness_division * DUTY_CYCLE
  );
}

int initialize_triac_gpio(void)
{
  int err = 0;

  if (triac.port && !device_is_ready(triac.port)) {
  printk("Error %d: LED device %s is not ready; ignoring it\n",
         err, triac.port->name);
  triac.port = NULL;
  err += -ENODEV;
  }
  if (triac.port) {
    err = gpio_pin_configure_dt(&triac, GPIO_OUTPUT);
    if (err != 0) {
      printk("Error %d: failed to configure LED device %s pin %d\n",
             err, triac.port->name, triac.pin);
      triac.port = NULL;
    } else {
      printk("Set up LED at %s pin %d\n", triac.port->name, triac.pin);
    }
  } else {
    printk("There is no triac port\n");
  }

  return err;
}

int init_triac_controller(void)
{
  int err = 0;

  err += k_sem_init(&triac_enabled_sem, 1, 1);
  err += k_sem_init(&brightness_level_sem, 1, 1);

  calculate_time_frame();
  err += initialize_triac_gpio();

  return err;
}

void change_triac_enabled_state(bool enabled_state)
{
  if(0 == k_sem_take(&triac_enabled_sem, K_MSEC(100))) {
    triac_enabled = enabled_state;
    k_sem_give(&triac_enabled_sem);
  }
}

void change_triac_brightness_level(uint8_t brightness_level)
{
  if(
    LOWEST_BRIGHTNESS_LEVEL <= brightness_level 
      && 
    HIGHEST_BRIGHTNESS_LEVEL >= brightness_level
  ) {
    if(0 == k_sem_take(&brightness_level_sem, K_MSEC(100))) {
      triac_brightness_level = brightness_level;
      k_sem_give(&brightness_level_sem);
    }
  }
}
```

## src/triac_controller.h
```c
/******************************************************************************************
 *
 * @file        triac_controller.h
 *
 * @brief       Controls Triac On/Off states
 *
 * @details     Accepts inputs for if Triac is enabled/disabled, and for how long
 *
 * @author(s)   Joe Rippee
 *
 * @created     2/12/2024   (MM/DD/YYYY)
 * 
 * @copyright       © 2024 SWYM, LLC. All Rights Reserved
 *
 *****************************************************************************************/

#ifndef TRIAC_CONTROLLER_H__
#define TRIAC_CONTROLLER_H__

#include <stdint.h>

/*
  Parameter: void function pointer for when new AC wave is detected
  Returns: status variable for ac wave detection initialization. 0 = success

  Initializes the ac wave detector with edge detect interrupts (rising edge only)
  Provided callback is stored in a unique private function pointer
*/
int init_triac_controller(void);
void start_triac_on_timer(void);
void change_triac_enabled_state(bool enabled_state);
void change_triac_brightness_level(uint8_t brightness_level);

#endif
```

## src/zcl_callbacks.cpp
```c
/*
 * Copyright (c) 2021 Nordic Semiconductor ASA
 *
 * SPDX-License-Identifier: LicenseRef-Nordic-5-Clause
 */

#include <lib/support/logging/CHIPLogging.h>

extern "C" {
    #include "triac_controller.h"
}

#include "app_task.h"

#ifdef CONFIG_AWS_IOT_INTEGRATION
#include "aws_iot_integration.h"
#endif

#include <app-common/zap-generated/attributes/Accessors.h>
#include <app-common/zap-generated/ids/Attributes.h>
#include <app-common/zap-generated/ids/Clusters.h>
#include <app/ConcreteAttributePath.h>

using namespace ::chip;
using namespace ::chip::app::Clusters;
using namespace ::chip::app::Clusters::OnOff;

void MatterPostAttributeChangeCallback(const chip::app::ConcreteAttributePath &attributePath, uint8_t type,
				       uint16_t size, uint8_t *value)
{
	ClusterId clusterId = attributePath.mClusterId;
	AttributeId attributeId = attributePath.mAttributeId;

	if (clusterId == OnOff::Id && attributeId == OnOff::Attributes::OnOff::Id) {
		ChipLogProgress(Zcl, "Cluster OnOff: attribute OnOff set to %" PRIu8 "", *value);
        printk("[zcl_callbacks] The cluster is being turn: %" PRIu8 "\n", *value);
        (*value) ? change_triac_brightness_level(1) : change_triac_brightness_level(10);

		AppTask::Instance().GetPWMDevice().InitiateAction(*value ? Nrf::PWMDevice::ON_ACTION : Nrf::PWMDevice::OFF_ACTION,
								  static_cast<int32_t>(LightingActor::Remote), value);

#ifdef CONFIG_AWS_IOT_INTEGRATION
		aws_iot_integration_attribute_set(ATTRIBUTE_ID_ONOFF, *value);
#endif

	} else if (clusterId == LevelControl::Id && attributeId == LevelControl::Attributes::CurrentLevel::Id) {
		ChipLogProgress(Zcl, "Cluster LevelControl: attribute CurrentLevel set to %" PRIu8 "", *value);
        printk("[zcl_callbacks] The cluster brightness is: %" PRIu8 "\n", *value);
        uint8_t mapped_value = 10 - ((*value - 3) * 9) / 251;
//        change_triac_enabled_state(true);
        change_triac_brightness_level(mapped_value);
		if (AppTask::Instance().GetPWMDevice().IsTurnedOn()) {
			AppTask::Instance().GetPWMDevice().InitiateAction(
				Nrf::PWMDevice::LEVEL_ACTION, static_cast<int32_t>(LightingActor::Remote), value);
		} else {
			ChipLogDetail(Zcl, "LED is off. Try to use move-to-level-with-on-off instead of move-to-level");
		}

#ifdef CONFIG_AWS_IOT_INTEGRATION
		aws_iot_integration_attribute_set(ATTRIBUTE_ID_LEVEL_CONTROL, *value);
#endif
	}
}

/** @brief OnOff Cluster Init
 *
 * This function is called when a specific cluster is initialized. It gives the
 * application an opportunity to take care of cluster initialization procedures.
 * It is called exactly once for each endpoint where cluster is present.
 *
 * @param endpoint   Ver.: always
 *
 * TODO Issue #3841
 * emberAfOnOffClusterInitCallback happens before the stack initialize the cluster
 * attributes to the default value.
 * The logic here expects something similar to the deprecated Plugins callback
 * emberAfPluginOnOffClusterServerPostInitCallback.
 *
 */
void emberAfOnOffClusterInitCallback(EndpointId endpoint)
{
	EmberAfStatus status;
	bool storedValue;

	/* Read storedValue on/off value */
	status = Attributes::OnOff::Get(endpoint, &storedValue);
	if (status == EMBER_ZCL_STATUS_SUCCESS) {
		/* Set actual state to the cluster state that was last persisted */
		AppTask::Instance().GetPWMDevice().InitiateAction(
			storedValue ? Nrf::PWMDevice::ON_ACTION : Nrf::PWMDevice::OFF_ACTION,
			static_cast<int32_t>(LightingActor::Remote), reinterpret_cast<uint8_t *>(&storedValue));
	}

	AppTask::Instance().UpdateClusterState();
}
```
